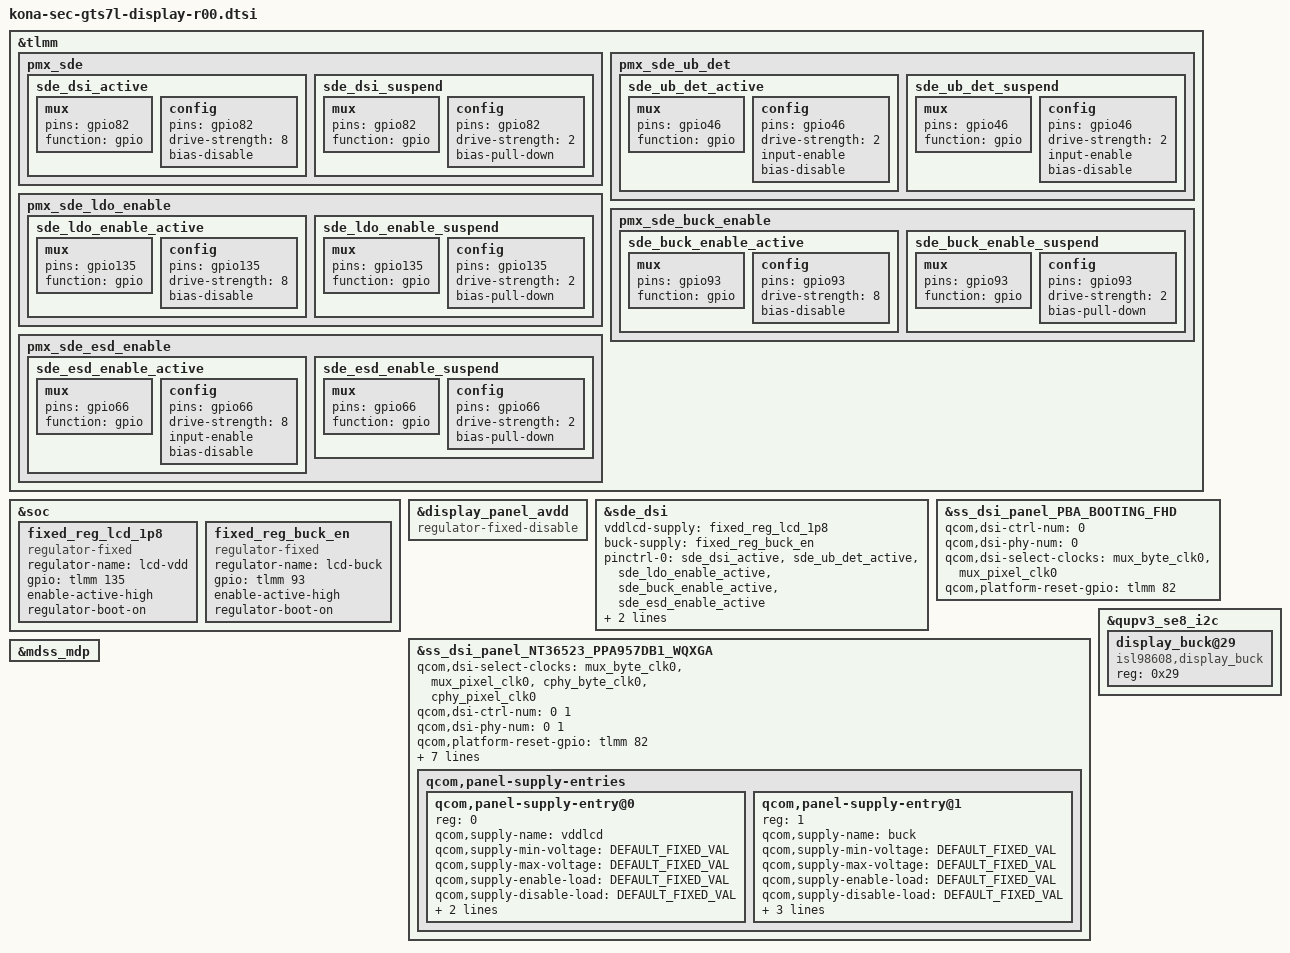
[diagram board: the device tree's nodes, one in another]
/* Copyright (c) 2016-2017, The Linux Foundation. All rights reserved.
 *
 * This program is free software; you can redistribute it and/or modify
 * it under the terms of the GNU General Public License version 2 and
 * only version 2 as published by the Free Software Foundation.
 *
 * This program is distributed in the hope that it will be useful,
 * but WITHOUT ANY WARRANTY; without even the implied warranty of
 * MERCHANTABILITY or FITNESS FOR A PARTICULAR PURPOSE.  See the
 * GNU General Public License for more details.
 */
#include <dt-bindings/pinctrl/qcom,pmic-gpio.h>
#include "../../../../../../techpack/display/msm/samsung/NT36523_PPA957DB1/dsi_panel_NT36523_PPA957DB1_wqxga_video.dtsi"
#include "../../../../../../techpack/display/msm/samsung/PBA_BOOTING/dsi_panel_PBA_BOOTING_fhd_video.dtsi"

#define DEFAULT_FIXED_VAL	0

&tlmm {
	pmx_sde: pmx_sde {
		sde_dsi_active: sde_dsi_active {
			mux {
				pins = "gpio82";
				function = "gpio";
			};

			config {
				pins = "gpio82";
				drive-strength = <8>;   /* 8 mA */
				bias-disable;           /* NO PULL */
			};
		};
		sde_dsi_suspend: sde_dsi_suspend {
			mux {
				pins = "gpio82";
				function = "gpio";
			};

			config {
				pins = "gpio82";
				drive-strength = <2>;   /* 2 mA */
				bias-pull-down;         /* PULL DOWN */
			};
		};
	};

	pmx_sde_ub_det {
		sde_ub_det_active: sde_ub_det_active {
			mux {
				pins = "gpio46";
				function = "gpio";
			};

			config {
				pins = "gpio46";
				drive-strength = <2>;
				input-enable;
				bias-disable;           /* NO PULL */
			};
		};

		sde_ub_det_suspend: sde_ub_det_suspend {
			mux {
				pins = "gpio46";
				function = "gpio";
			};

			config {
				pins = "gpio46";
				drive-strength = <2>;   /* 8 mA */
				input-enable;
				bias-disable;           /* NO PULL */
			};
		};
	};

	pmx_sde_ldo_enable {
		sde_ldo_enable_active: sde_ldo_enable_active {
			mux {
				pins = "gpio135";
				function = "gpio";
			};

			config {
				pins = "gpio135";
				drive-strength = <8>;
				bias-disable;           /* NO PULL */
			};
		};

		sde_ldo_enable_suspend: sde_ldo_enable_suspend {
			mux {
				pins = "gpio135";
				function = "gpio";
			};

			config {
				pins = "gpio135";
				drive-strength = <2>;
				bias-pull-down; /* PULL DOWN */
			};
		};
	};

	pmx_sde_buck_enable {
		sde_buck_enable_active: sde_buck_enable_active {
			mux {
				pins = "gpio93";
				function = "gpio";
			};

			config {
				pins = "gpio93";
				drive-strength = <8>;
				bias-disable;           /* NO PULL */
			};
		};

		sde_buck_enable_suspend: sde_buck_enable_suspend {
			mux {
				pins = "gpio93";
				function = "gpio";
			};

			config {
				pins = "gpio93";
				drive-strength = <2>;
				bias-pull-down; /* PULL DOWN */
			};
		};
	};

	pmx_sde_esd_enable {
		sde_esd_enable_active: sde_esd_enable_active {
			mux {
				pins = "gpio66";
				function = "gpio";
			};

			config {
				pins = "gpio66";
				drive-strength = <8>;
				input-enable;
				bias-disable;           /* NO PULL */
			};
		};

		sde_esd_enable_suspend: sde_esd_enable_suspend {
			mux {
				pins = "gpio66";
				function = "gpio";
			};

			config {
				pins = "gpio66";
				drive-strength = <2>;
				bias-pull-down; /* PULL DOWN */
			};
		};
	};
};

&soc {
	fixed_reg_lcd_1p8: fixed_reg_lcd_1p8 {
		compatible = "regulator-fixed";
		regulator-name = "lcd-vdd";
		gpio = <&tlmm 135 0>;
		enable-active-high;
		regulator-boot-on;
	};

	fixed_reg_buck_en: fixed_reg_buck_en {
		compatible = "regulator-fixed";
		regulator-name = "lcd-buck";
		gpio = <&tlmm 93 0>;
		enable-active-high;
		regulator-boot-on;
	};
};


/* display_panel_avdd node, in kona-sde-display.dtsi file, is gpio regualtor.
 * So, even SS doesn't enable the regulator, gpio61 is always registered as fixed regulator,
 * even it is for the other module, like audio i2c...
 * change compatible name to unused name, prevent to call probe of fixed regulator.
 */
&display_panel_avdd {
	compatible = "regulator-fixed-disable";
};

/* override display-list / supply for samsung panel */
&sde_dsi {

	/* te gpio is used for esd detection */
	/delete-property/qcom,platform-te-gpio;

	vddlcd-supply = <&fixed_reg_lcd_1p8>;
	buck-supply = <&fixed_reg_buck_en>;

	pinctrl-names = "panel_active", "panel_suspend";
	pinctrl-0 = <&sde_dsi_active &sde_ub_det_active &sde_ldo_enable_active &sde_buck_enable_active &sde_esd_enable_active>;
	pinctrl-1 = <&sde_ub_det_suspend &sde_esd_enable_suspend>;
};

&ss_dsi_panel_PBA_BOOTING_FHD {
	qcom,dsi-ctrl-num = <0>;
	qcom,dsi-phy-num = <0>;
	qcom,dsi-select-clocks = "mux_byte_clk0", "mux_pixel_clk0";

	qcom,platform-reset-gpio = <&tlmm 82 0>;
};


&ss_dsi_panel_NT36523_PPA957DB1_WQXGA {
	qcom,dsi-select-clocks = "mux_byte_clk0", "mux_pixel_clk0",
			"cphy_byte_clk0", "cphy_pixel_clk0";
	qcom,dsi-ctrl-num = <0 1>;
	qcom,dsi-phy-num = <0 1>;

	qcom,platform-reset-gpio = <&tlmm 82 0>;

	samsung,esd-irq-gpio1= <&tlmm 66 0>;
	qcom,mdss-dsi-panel-status-irq-trigger1 = "rising";

	samsung,ub-con-det = <&tlmm 46 0>;
	samsung,esd-irq-gpio2= <&tlmm 46 0>;
	qcom,mdss-dsi-panel-status-irq-trigger2 = "rising";

	qcom,panel-supply-entries {
		#address-cells = <1>;
		#size-cells = <0>;

		/* use fixed regulator instead of samsung,panel-extra-power-gpio
		 * or qcom,platform-enable-gpio. */
		/* VDD 1.8V */
		qcom,panel-supply-entry@0 {
			reg = <0>;
			qcom,supply-name = "vddlcd";
			qcom,supply-min-voltage = <DEFAULT_FIXED_VAL>;
			qcom,supply-max-voltage = <DEFAULT_FIXED_VAL>;
			qcom,supply-enable-load = <DEFAULT_FIXED_VAL>;
			qcom,supply-disable-load = <DEFAULT_FIXED_VAL>;
			qcom,supply-pre-off-sleep = <0>;
			qcom,supply-post-on-sleep = <0>;
		};

		qcom,panel-supply-entry@1 {
		    reg = <1>;
		    qcom,supply-name = "buck";
		    qcom,supply-min-voltage = <DEFAULT_FIXED_VAL>;
		    qcom,supply-max-voltage = <DEFAULT_FIXED_VAL>;
		    qcom,supply-enable-load = <DEFAULT_FIXED_VAL>;
		    qcom,supply-disable-load = <DEFAULT_FIXED_VAL>;
		    qcom,supply-pre-off-sleep = <0>;
		    qcom,supply-post-off-sleep = <10>; //discharging time
		    qcom,supply-post-on-sleep = <10>; //boosting time
		};
	};
};

&qupv3_se8_i2c {
	status = "ok";

	display_buck@29{
		compatible = "isl98608,display_buck";
		reg = <0x29>;
	};
};

&mdss_mdp {
	/*
		origin clock init rate is
		clock-rate = <0 0 0 0 300000000 19200000 300000000 19200000>;

		There is abnormal display issue. High mdp clock has effect on abnormal display issue.
		So, change init rate(for kerenl jump init rate) & mdp clock calculation fudge fatcot value.
	*/
	//clock-rate = <0 0 0 0 345000000  19200000 345000000  19200000>;
	//qcom,sde-core-clk-ff = "1.15";
};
